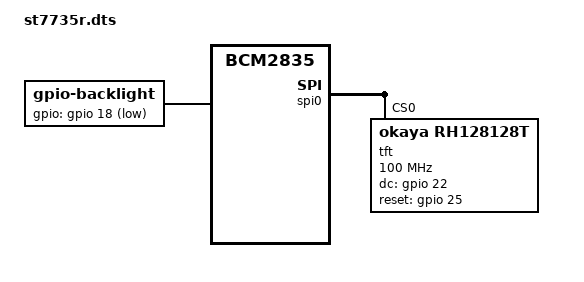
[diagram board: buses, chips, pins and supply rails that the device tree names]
/dts-v1/;
/plugin/;

/ {
	compatible = "brcm,bcm2835";

	fragment@0 {
		target-path = "/";

		__overlay__ {
			backlight {
				compatible = "gpio-backlight";
				gpios = <&gpio 18 1>;
				default-on;
			};
		};
	};

	fragment@1 {
		target = <&spi0>;
		__overlay__ {
			status = "okay";
			tft: st7735r@0 {
				#address-cells = <1>;
				#size-cells = <1>;
				compatible = "okaya,rh128128t";
				reg = <0>;
				spi-max-frequency = <100000000>;
				// buswidth = <8>;
				spi-cpol;
				spi-cpha;
				// blk-gpios = <&gpio 18 1>;
				// backlight = <&backlight>;
				dc-gpios = <&gpio 22 0>;
				reset-gpios = <&gpio 25 0>;
				status = "okay";
			};
		};
	};
};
